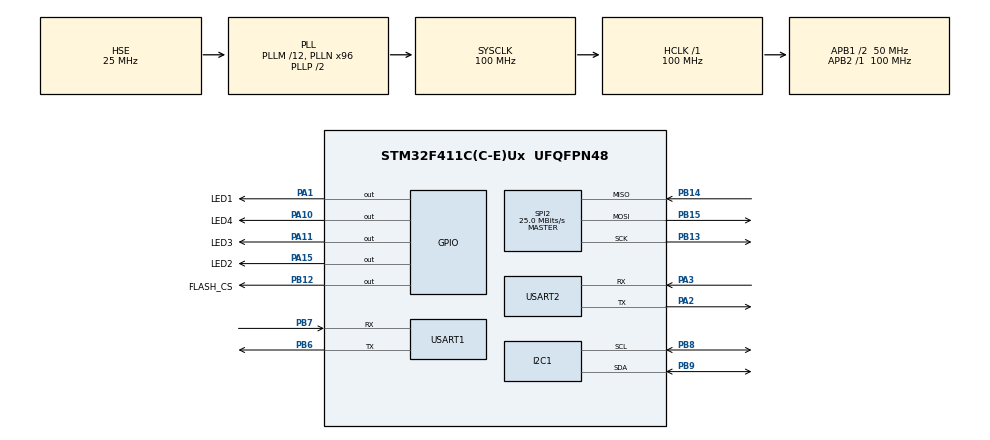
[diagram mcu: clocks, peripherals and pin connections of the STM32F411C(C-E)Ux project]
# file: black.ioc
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Dma.Request0=USART1_TX
Dma.Request1=USART2_TX
Dma.Request2=USART2_RX
Dma.Request3=USART1_RX
Dma.USART1_RX.3.Direction=DMA_PERIPH_TO_MEMORY
Dma.USART1_RX.3.FIFOMode=DMA_FIFOMODE_DISABLE
Dma.USART1_RX.3.Instance=DMA2_Stream2
Dma.USART1_RX.3.MemDataAlignment=DMA_MDATAALIGN_BYTE
Dma.USART1_RX.3.MemInc=DMA_MINC_ENABLE
Dma.USART1_RX.3.Mode=DMA_NORMAL
Dma.USART1_RX.3.PeriphDataAlignment=DMA_PDATAALIGN_BYTE
Dma.USART1_RX.3.PeriphInc=DMA_PINC_DISABLE
Dma.USART1_RX.3.Priority=DMA_PRIORITY_LOW
Dma.USART1_TX.0.Direction=DMA_MEMORY_TO_PERIPH
Dma.USART1_TX.0.FIFOMode=DMA_FIFOMODE_DISABLE
Dma.USART1_TX.0.Instance=DMA2_Stream7
Dma.USART1_TX.0.MemDataAlignment=DMA_MDATAALIGN_BYTE
Dma.USART1_TX.0.MemInc=DMA_MINC_ENABLE
Dma.USART1_TX.0.Mode=DMA_NORMAL
Dma.USART1_TX.0.PeriphDataAlignment=DMA_PDATAALIGN_BYTE
Dma.USART1_TX.0.PeriphInc=DMA_PINC_DISABLE
Dma.USART1_TX.0.Priority=DMA_PRIORITY_LOW
Dma.USART2_RX.2.Direction=DMA_PERIPH_TO_MEMORY
Dma.USART2_RX.2.FIFOMode=DMA_FIFOMODE_DISABLE
Dma.USART2_RX.2.Instance=DMA1_Stream5
Dma.USART2_RX.2.MemDataAlignment=DMA_MDATAALIGN_BYTE
Dma.USART2_RX.2.MemInc=DMA_MINC_ENABLE
Dma.USART2_RX.2.Mode=DMA_NORMAL
Dma.USART2_RX.2.PeriphDataAlignment=DMA_PDATAALIGN_BYTE
Dma.USART2_RX.2.PeriphInc=DMA_PINC_DISABLE
Dma.USART2_RX.2.Priority=DMA_PRIORITY_LOW
Dma.USART2_TX.1.Direction=DMA_MEMORY_TO_PERIPH
Dma.USART2_TX.1.FIFOMode=DMA_FIFOMODE_DISABLE
Dma.USART2_TX.1.Instance=DMA1_Stream6
Dma.USART2_TX.1.MemDataAlignment=DMA_MDATAALIGN_BYTE
Dma.USART2_TX.1.MemInc=DMA_MINC_ENABLE
Dma.USART2_TX.1.Mode=DMA_NORMAL
Dma.USART2_TX.1.PeriphDataAlignment=DMA_PDATAALIGN_BYTE
Dma.USART2_TX.1.PeriphInc=DMA_PINC_DISABLE
Dma.USART2_TX.1.Priority=DMA_PRIORITY_LOW
I2C1.I2C_Mode=I2C_Fast
Mcu.Family=STM32F4
Mcu.Name=STM32F411C(C-E)Ux
Mcu.Package=UFQFPN48
NVIC.DMA1_Stream5_IRQn=true\:0\:0\:false\:false\:false\:false\:false
NVIC.DMA1_Stream6_IRQn=true\:0\:0\:false\:false\:false\:false\:false
NVIC.DMA2_Stream2_IRQn=true\:0\:0\:false\:false\:false\:false\:false
NVIC.DMA2_Stream7_IRQn=true\:0\:0\:false\:false\:false\:false\:false
NVIC.PriorityGroup=NVIC_PRIORITYGROUP_4
NVIC.TIM1_TRG_COM_TIM11_IRQn=true\:0\:0\:false\:false\:true\:false\:true
NVIC.TimeBase=TIM1_TRG_COM_TIM11_IRQn
NVIC.TimeBaseIP=TIM11
NVIC.USART1_IRQn=true\:0\:0\:false\:false\:false\:true\:false
NVIC.USART2_IRQn=true\:0\:0\:false\:false\:false\:true\:false
PA1.GPIO_Label=LED1
PA1.Signal=GPIO_Output
PA10.GPIO_Label=LED4
PA10.Signal=GPIO_Output
PA11.GPIO_Label=LED3
PA11.Signal=GPIO_Output
PA15.GPIO_Label=LED2
PA15.Signal=GPIO_Output
PA2.Mode=Asynchronous
PA2.Signal=USART2_TX
PA3.Mode=Asynchronous
PA3.Signal=USART2_RX
PB12.GPIO_Label=FLASH_CS
PB12.PinState=GPIO_PIN_SET
PB12.Signal=GPIO_Output
PB13.Mode=Full_Duplex_Master
PB13.Signal=SPI2_SCK
PB14.Mode=Full_Duplex_Master
PB14.Signal=SPI2_MISO
PB15.Mode=Full_Duplex_Master
PB15.Signal=SPI2_MOSI
PB6.Mode=Asynchronous
PB6.Signal=USART1_TX
PB7.Mode=Asynchronous
PB7.Signal=USART1_RX
PB8.Mode=I2C
PB8.Signal=I2C1_SCL
PB9.Mode=I2C
PB9.Signal=I2C1_SDA
PH0\ -\ OSC_IN.Mode=HSE-External-Clock-Source
PH0\ -\ OSC_IN.Signal=RCC_OSC_IN
PH1\ -\ OSC_OUT.Mode=HSE-External-Clock-Source
PH1\ -\ OSC_OUT.Signal=RCC_OSC_OUT
ProjectManager.HeapSize=0x200
ProjectManager.StackSize=0x400
ProjectManager.TargetToolchain=MDK-ARM V5.27
RCC.48MHZClocksFreq_Value=50000000
RCC.AHBFreq_Value=100000000
RCC.APB1CLKDivider=RCC_HCLK_DIV2
RCC.APB1Freq_Value=50000000
RCC.APB1TimFreq_Value=100000000
RCC.APB2Freq_Value=100000000
RCC.APB2TimFreq_Value=100000000
RCC.CortexFreq_Value=100000000
RCC.HCLKFreq_Value=100000000
RCC.HSE_VALUE=25000000
RCC.HSI_VALUE=16000000
RCC.LSE_VALUE=32768
RCC.PLLM=12
RCC.PLLN=96
RCC.PLLSourceVirtual=RCC_PLLSOURCE_HSE
RCC.SYSCLKFreq_VALUE=100000000
RCC.SYSCLKSource=RCC_SYSCLKSOURCE_PLLCLK
RCC.VCOOutputFreq_Value=200000000
SPI2.BaudRatePrescaler=SPI_BAUDRATEPRESCALER_2
SPI2.CalculateBaudRate=25.0 MBits/s
SPI2.Direction=SPI_DIRECTION_2LINES
SPI2.Mode=SPI_MODE_MASTER
SPI2.VirtualType=VM_MASTER
USART1.VirtualMode=VM_ASYNC
USART2.VirtualMode=VM_ASYNC
VP_CRC_VS_CRC.Mode=CRC_Activate
VP_SYS_VS_tim11.Mode=TIM11
board=custom

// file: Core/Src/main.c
/* USER CODE BEGIN Header */
/**
  ******************************************************************************
  * @file           : main.c
  * @brief          : Main program body
  ******************************************************************************
  * @attention
  *
  * <h2><center>&copy; Copyright (c) 2019 STMicroelectronics.
  * All rights reserved.</center></h2>
  *
  * This software component is licensed by ST under BSD 3-Clause license,
  * the "License"; You may not use this file except in compliance with the
  * License. You may obtain a copy of the License at:
  *                        opensource.org/licenses/BSD-3-Clause
  *
  ******************************************************************************
  */
/* USER CODE END Header */

#include "main.h"
#include "crc.h"
#include "dma.h"
#include "i2c.h"
#include "spi.h"
#include "usart.h"
#include "gpio.h"

/* USER CODE BEGIN Includes */
#include "rtx_main.h"
/* USER CODE END Includes */

void SystemClock_Config(void);

int main(void)
{

  /* MCU Configuration--------------------------------------------------------*/

  /* Reset of all peripherals, Initializes the Flash interface and the Systick. */
  HAL_Init();

  /* Configure the system clock */
  SystemClock_Config();

  /* Initialize all configured peripherals */
  MX_GPIO_Init();
  MX_DMA_Init();
  MX_USART1_UART_Init();
  MX_I2C1_Init();
  MX_USART2_UART_Init();
  MX_SPI2_Init();
  MX_CRC_Init();
  /* USER CODE BEGIN 2 */
	rtx_main();
  /* USER CODE END 2 */

  /* Infinite loop */
  while (1)
  {

    /* USER CODE BEGIN 3 */
	  //HAL_UART_Transmit_DMA(&huart1, "1111", 4);
	 // HAL_UART_Transmit_DMA(&huart2, "huart2", 6);

  }
  /* USER CODE END 3 */
}

void SystemClock_Config(void)
{
  RCC_OscInitTypeDef RCC_OscInitStruct = {0};
  RCC_ClkInitTypeDef RCC_ClkInitStruct = {0};

  /** Configure the main internal regulator output voltage
  */
  __HAL_RCC_PWR_CLK_ENABLE();
  __HAL_PWR_VOLTAGESCALING_CONFIG(PWR_REGULATOR_VOLTAGE_SCALE1);
  /** Initializes the CPU, AHB and APB busses clocks
  */
  RCC_OscInitStruct.OscillatorType = RCC_OSCILLATORTYPE_HSE;
  RCC_OscInitStruct.HSEState = RCC_HSE_BYPASS;
  RCC_OscInitStruct.PLL.PLLState = RCC_PLL_ON;
  RCC_OscInitStruct.PLL.PLLSource = RCC_PLLSOURCE_HSE;
  RCC_OscInitStruct.PLL.PLLM = 12;
  RCC_OscInitStruct.PLL.PLLN = 96;
  RCC_OscInitStruct.PLL.PLLP = RCC_PLLP_DIV2;
  RCC_OscInitStruct.PLL.PLLQ = 4;
  if (HAL_RCC_OscConfig(&RCC_OscInitStruct) != HAL_OK)
  {
    Error_Handler();
  }
  /** Initializes the CPU, AHB and APB busses clocks
  */
  RCC_ClkInitStruct.ClockType = RCC_CLOCKTYPE_HCLK|RCC_CLOCKTYPE_SYSCLK
                              |RCC_CLOCKTYPE_PCLK1|RCC_CLOCKTYPE_PCLK2;
  RCC_ClkInitStruct.SYSCLKSource = RCC_SYSCLKSOURCE_PLLCLK;
  RCC_ClkInitStruct.AHBCLKDivider = RCC_SYSCLK_DIV1;
  RCC_ClkInitStruct.APB1CLKDivider = RCC_HCLK_DIV2;
  RCC_ClkInitStruct.APB2CLKDivider = RCC_HCLK_DIV1;

  if (HAL_RCC_ClockConfig(&RCC_ClkInitStruct, FLASH_LATENCY_3) != HAL_OK)
  {
    Error_Handler();
  }
}

void HAL_TIM_PeriodElapsedCallback(TIM_HandleTypeDef *htim)
{
  if (htim->Instance == TIM11) {
    HAL_IncTick();
  }
}

void Error_Handler(void)
{
}

/************************ (C) COPYRIGHT STMicroelectronics *****END OF FILE****/
